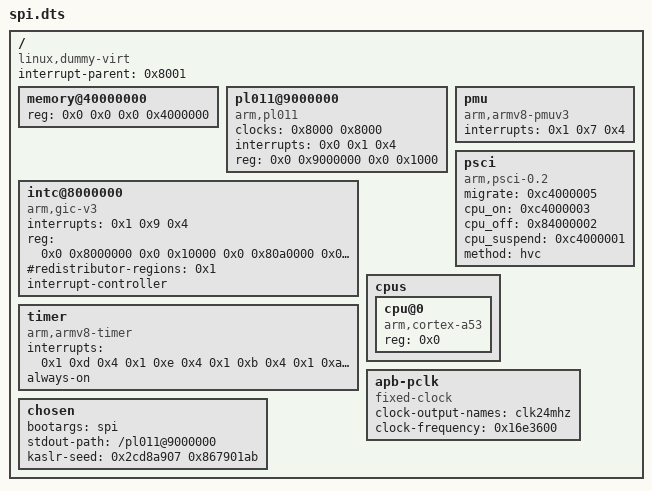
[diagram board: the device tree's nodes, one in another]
/dts-v1/;

/ {
	interrupt-parent = <0x8001>;
	#size-cells = <0x2>;
	#address-cells = <0x2>;
	compatible = "linux,dummy-virt";

	memory@40000000 {
		reg = <0x0 0x0 0x0 0x4000000>;
		device_type = "memory";
	};

	pl011@9000000 {
		clock-names = "uartclk", "apb_pclk";
		clocks = <0x8000 0x8000>;
		interrupts = <0x0 0x1 0x4>;
		reg = <0x0 0x9000000 0x0 0x1000>;
		compatible = "arm,pl011", "arm,primecell";
	};

	pmu {
		interrupts = <0x1 0x7 0x4>;
		compatible = "arm,armv8-pmuv3";
	};

	intc@8000000 {
		phandle = <0x8001>;
		interrupts = <0x1 0x9 0x4>;
		reg = <0x0 0x8000000 0x0 0x10000 0x0 0x80a0000 0x0 0xf60000>;
		#redistributor-regions = <0x1>;
		compatible = "arm,gic-v3";
		ranges;
		#size-cells = <0x2>;
		#address-cells = <0x2>;
		interrupt-controller;
		#interrupt-cells = <0x3>;
	};

	psci {
		migrate = <0xc4000005>;
		cpu_on = <0xc4000003>;
		cpu_off = <0x84000002>;
		cpu_suspend = <0xc4000001>;
		method = "hvc";
		compatible = "arm,psci-0.2", "arm,psci";
	};


	cpus {
		#size-cells = <0x0>;
		#address-cells = <0x1>;

		cpu@0 {
			reg = <0x0>;
			compatible = "arm,cortex-a53";
			device_type = "cpu";
		};
	};

	timer {
		interrupts = <0x1 0xd 0x4 0x1 0xe 0x4 0x1 0xb 0x4 0x1 0xa 0x4>;
		always-on;
		compatible = "arm,armv8-timer", "arm,armv7-timer";
	};

	apb-pclk {
		phandle = <0x8000>;
		clock-output-names = "clk24mhz";
		clock-frequency = <0x16e3600>;
		#clock-cells = <0x0>;
		compatible = "fixed-clock";
	};

	chosen {
		bootargs = "spi";
		stdout-path = "/pl011@9000000";
		kaslr-seed = <0x2cd8a907 0x867901ab>;
	};
};
